# cslr_ul2_001 register map
Vendor: Texas Instruments
Peripheral module from a debugger description file.
Registers are 32-bit, read-write, reset 0x0 unless marked. A register's access mark holds for its fields unless they carry their own. Offsets are as the file gives them; lines under a group give offsets from that group; [hi:lo] are bit positions; {n}, {i} and the like mark numbered series; 'fields as' and 'values as' point back to an identical list; <NAME> marks a mode.

## UTOPIA2 — UNIVERSAL TEST AND OPERATIONS INTERFACE FOR ASYNCHRONOUS TRANSFER MODE
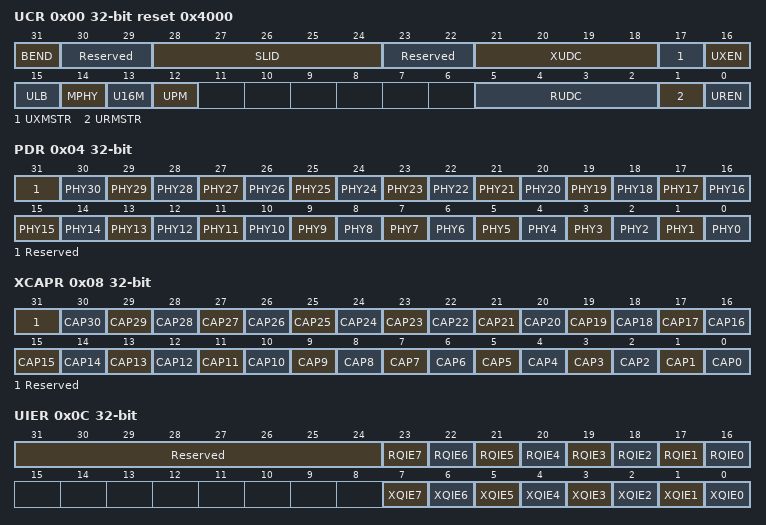
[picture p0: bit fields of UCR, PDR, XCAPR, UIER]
0x00 UCR access not given reset 0x4000 (reset mask 0x803FF03F) — UTOPIA Control Register
  [31] BEND rw — Endian Mode for data transferred via UTOPIA interface.
  [30:29] Reserved — (access N)
  [28:24] SLID SLEND rw — Slave ID: Applicable in Slave and MPHY mode.Slave END:Applicable in Master and MPHY mode.
  [23:22] Reserved — (access N)
  [21:18] XUDC rw — Transmit User Defined Cell
    0=? (Transmits standard ATM cell size of 53B); 11=? (Applicable for slave mode only. Transmits 11 extra header bytes)
  [17] UXMSTR rw — UTOPIA Transmit in master or slave mode selection
  [16] UXEN rw — UTOPIA Transmitter Enable
    0=? (UTOPIA port Transmitter Disabled and in reset state.); 1=? (UTOPIA port Transmitter Enabled.)
  [15] ULB rw — UTOPIA Loop Back Mode
    0=? (loop back mode disabled and normal UTOPIA operation); 1=? (loop back mode enabled.Master/Slave selection via U(R/X)MSTR)
  [14] MPHY rw — UTOPIA Receive/Transmit Multi-PHY Mode. MPHY mode is by default.
    0=? (Single PHY mode selected.); 1=? (Multi-PHY mode selected.)
  [13] U16M rw — 8-bit/16-bit Mode . 8-bit operation is default mode
    0=? (8-bit operation on both transmit and receive UTOPIA interface); 1=? (16-bit operation on both transmit and receive UTOPIA interface)
  [12] UPM rw — UTOPIA polling mode .Valid only when UMSTR=1
    0=? (Round-robin polling is used.); 1=? (Fixed address polling is used.)
  [5:2] RUDC rw — Receive User Defined Cell
    0=? (Receives standard ATM cell size of 53B); 11=? (Applicable for slave mode only. Receives 11 extra header bytes)
  [1] URMSTR rw — UTOPIA receive in master or slave mode selection
    0=? (Transmit and Receive interface are in slave mode :default state); 1=? (Transmit and Receive interface are in master mode)
  [0] UREN rw — UTOPIA Receiver Enable
    0=? (UTOPIA port receiver is disabled and in reset state); 1=? (UTOPIA port receiver is enabled)
0x04 PDR access not given (reset mask 0x7FFFFFFF) — PHY Disable Register
  [31] Reserved — (access N)
  [n] PHY{n} rw (n=0..30) — When Set PHY{n} is disabled
0x08 XCAPR access not given (reset mask 0x7FFFFFFF) — Transmit Cell Available for PHY Register(XCAPR)
  [31] Reserved — (access N)
  [n] CAP{n} ro (n=0..30) — Transmit Cell Available for PHY {n}
0x0C UIER access not given (reset mask 0xFF00FF) — UTOPIA Interrupt Enable Register
  [31:24] Reserved — (access N)
  [n+16] RQIE{n} rw (n=0..7) — Receive Queue Interrupt {n} enable
  [n] XQIE{n} rw (n=0..7) — Transmit Queue Interrupt {n} enable
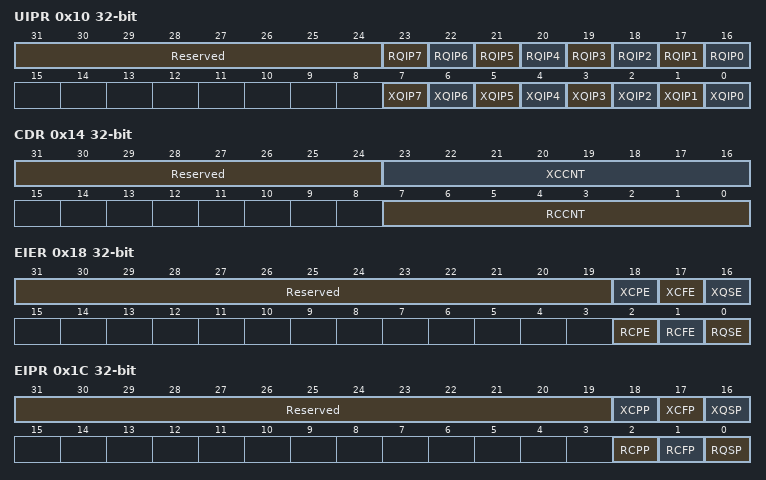
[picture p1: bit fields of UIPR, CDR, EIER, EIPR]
0x10 UIPR access not given (reset mask 0xFF00FF) — UTOPIA Interrupt Pending Register
  [31:24] Reserved — (access N)
  [n+16] RQIP{n} rw (n=0..7) — Receive Queue Interrupt Pending {n} is captured in UIPR
  [n] XQIP{n} rw (n=0..7) — Transmit Queue Interrupt Pending {n} is captured in UIPR
0x14 CDR access not given (reset mask 0xFF00FF) — Clock Detect Register
  [31:24] Reserved — (access N)
  [23:16] XCCNT rw — Transmit Interface Clock Count value.
    0=XCCNT (Transmit Clock Detection Disabled.)
  [7:0] RCCNT rw — Receive Interface Clock Count value.
    0=RCCNT (Receive Clock Detection disabled)
0x18 EIER access not given (reset mask 0x70007) — ERROR Interrupt Enable Register
  [31:19] Reserved — (access N)
  [18] XCPE rw — Transmit Clock Present Interrupt Enable
    0=XCPE (Transmit Clock Present Interrupt Disabled); 1=XCPE (Transmit Clock Present Interrupt Enabled)
  [17] XCFE rw — Transmit Clock Failed Interrupt Enable
    0=XCFE (Transmit Clock Failed Interrupt Disabled); 1=XCFE (Transmit Clock Failed Interrupt Enabled)
  [16] XQSE rw — Transmit Queue Stall Interrupt Enable
    0=XQSE (Transmit Queue Stall Interrupt Disabled); 1=XQSE (Transmit Queue Stall Interrupt Enabled)
  [2] RCPE rw — Receive Clock Present Interrupt Enable
    0=RCPE (Receive Clock Present Interrupt Disabled); 1=RCPE (Receive Clock Present Interrupt Enabled)
  [1] RCFE rw — Receive Clock Failed Interrupt Enable
    0=RCFE (Receive Clock Failed Interrupt Disabled); 1=RCFE (Receive Clock Failed Interrupt Enabled)
  [0] RQSE rw — Receive Queue Stall Interrupt Enable
    0=RQSE (Receive Queue Stall Interrupt Disabled); 1=RQSE (Receive Queue Stall Interrupt Enabled)
0x1C EIPR access not given (reset mask 0x70007) — Error Interrupt Pending Register
  [31:19] Reserved — (access N)
  [18] XCPP rw — Transmit Clock Present Interrupt Pending.XCPP is valid regardless if UXEN is set or not.
    0=XCPP (UXCLK not present.); 1=XCPP (UXCLK present. If the corresponding bit in the EIER is set,an interrupt UINT is sent to the CPU.)
  [17] XCFP rw — Transmit Clock Failed Interrupt Pending.Activated only when UXEN=1.
    0=XCFP (UXCLK present.); 1=XCFP (UXCLK failed. If the corresponding bit in the EIER is set,an interrupt UINT is sent to the CPU.)
  [16] XQSP rw — Transmit Queue Stall Interrupt Pending.Stalled untill the queue is drained and space is available.
    0=XQSP (No Transmit Queue Stall condition.); 1=XQSP (Transmit Queue Stalled.XQSP is cleared once the queue has space available and writes can continue.)
  [2] RCPP rw — Receive Clock Present Interrupt Pending.RCPP is valid regardless if UREN is set or not.
    0=RCPP (URCLK not Present); 1=RCPP (URCLK present. If the corresponding bit in the EIER is set,an interrupt UINT is sent to the CPU.)
  [1] RCFP rw — Receive Clock Failed Interrupt Pending.Activated only when UTOPIA Receive Interface(UREN=1)
    0=RCFP (URCLK present.); 1=RCFP (URCLK failed.If corresponding bit in EIER is set,an interrupt UINT is sent to the CPU.)
  [0] RQSP rw — Receive Queue Stall Interrupt Pending
    0=RQSP (No Receive Queue Stall Condition); 1=RQSP (Receive Queue Stalled.RQSP is cleared as soon as Valid data is available and the read is performed.)
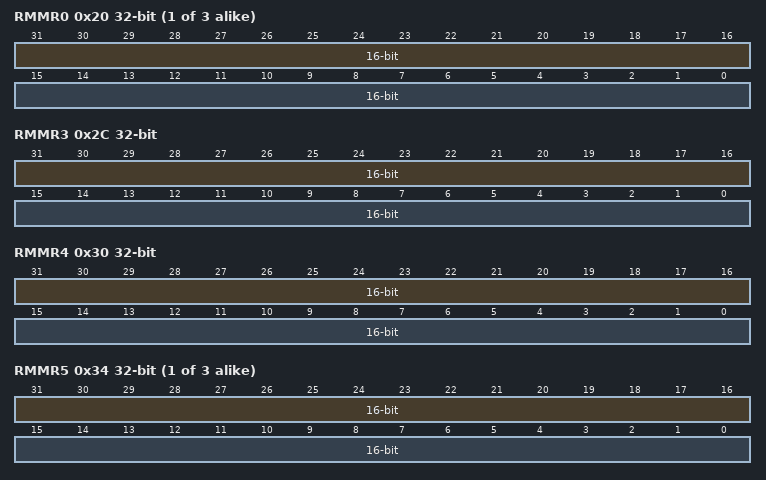
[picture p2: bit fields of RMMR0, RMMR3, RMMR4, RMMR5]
{0x20+4i} RMMR{i} (i=0..2) — Receive Mask-Match Register {i}
  [31:16] 16-bit MATCH value, [15:0] 16-bit MASK value
0x2C RMMR3 — Receive Mask-Match register3
  [31:16] 16-bit MATCH value, [15:0] 16-bit MASK value
0x30 RMMR4 — Receive Mask-Match Register4
  [31:16] 16-bit MATCH value, [15:0] 16-bit MASK value
{0x20+4i} RMMR{i} (i=5..7) — Receive Mask-Match register{i}
  [31:16] 16-bit MATCH value, [15:0] 16-bit MASK value
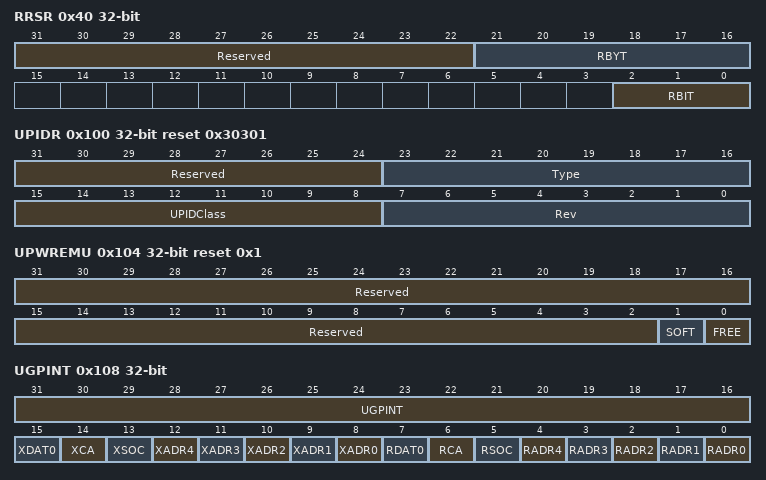
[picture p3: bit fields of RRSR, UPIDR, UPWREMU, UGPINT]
0x40 RRSR access not given (reset mask 0x3F0007) — Receive Routing Select Register
  [31:22] Reserved — (access N)
  [21:16] RBYT rw — Indicates Least Significant Byte of the 16-bit field of interest.
  [2:0] RBIT rw — Indicates the least significant bit within the 16-bit field of interest that is used for routing decisions.
0x100 UPIDR access not given reset 0x30301 (reset mask 0xFFFFFF) — Register to identify the peripheral for revision number,class,and type.
  [31:24] Reserved — (access N)
  [23:16] Type ro — The Type of peripheral specifies the actual peripheral within a peripheral Class. For UTOPIA, the Class in the UIPDR[Class] defines UTOPIA Level 2 interface.
  [15:8] UPIDClass ro — The Class indicates if the peripheral is a Host interface, DMA controller, or a Network Interface, etc. UTOPIA belongs to the Class - Network Interface that always carries a value '3'.
  [7:0] Rev ro — Reserved
0x104 UPWREMU access not given reset 0x1 (reset mask 0x3) — UTOPIA Power Management and Emulation Register
  [31:2] Reserved — (access N)
  [1] SOFT rw — This Bit has no effect when FREE=1.
    0=SOFT (Undefined Operation); 1=SOFT (In Slave mode all on-going operations should be complete.In master Mode Mode: Current data transfer on the pins should complete and pending read/write requests to/from CPU/DMA should complete before emulation halt.)
  [0] FREE rw — This Bit in conjunction with SOFT bit determines Emulation operation
    0=FREE (SOFT bit controls Emulation During Emulation Halt); 1=FREE (Emulation has no effect on UTOPIA port Operation.Peripheral operates Normally.)
0x108 UGPINT — GPIO Interrupts are Enabled
  [31:16] UGPINT — GPIO Interrupt Negation/Polarity
    0=UGPINT[x] (GPIO interrupt not inverted. Polarity remains same as that at the pin(s).); 1=UGPINT[x] (Relevant GPIO interrupt is inverted. It could be any of the pins.)
  [15] XDAT0 — Transmit data 0
    0=XDAT0 (GPIO interrupt disabled.); 1=XDAT1 (1, Low-to-high transition on the UXData[0] pin causes interrupt RQIP0 to CPU via UIPR and UIER. It can also generate DMA event XEVT0.)
  [14] XCA — Transmit Cell Available
    0=XCA (GPIO interrupt disabled.); 1=XCA (Low-to-high transition on the UXClav pin causes interrupt XQIP1 to CPU via UIPR and UIER. It can also generate DMA event XEVT1)
  [13] XSOC — Transmit Start of Cell
    0=XSOC (GPIO interrupt disabled.); 1=XSOC (Low-to-high transition on the UXSOC pin causes interrupt XQIP2 to CPU via UIPR and UIER. It can also generate DMA event XEVT2.)
  [n+8] XADR{n} (n=0..4) — Transmit address{n}
  [7] RDAT0 — Receive data0
    0=RDAT0 (GPIO interrupt disabled.); 1=RDAT1 (1, Low-to-high transition on the URData[0] pin causes interrupt RQIP0 to CPU via UIPR and UIER. It can also generate DMA event REVT0.)
  [6] RCA — Receive Cell Available
    0=RCA (GPIO interrupt Disabled.); 1=RCA (Low-to-high transition on the URClav pin causes interrupt RQIP1 to CPU via UIPR and UIER. It can also generate DMA event REVT1.)
  [5] RSOC — Receive Start of Cell
    0=RSOC (GPIO interrupt Disabled.); 1=RSOC (Low-to-high transition on the URSOC pin causes interrupt RQIP2 to CPU via UIPR and UIER. It can also generate DMA event REVT2.)
  [4] RADR4
  [3] RADR3 — REVT[7:3].
  [2] RADR2 — corresponding interrupts RQIP[7:3] to CPU via UIPR and UIER. It can also generate DMA event
  [1] RADR1 — RADR [4:0] = 1, Low-to-high transition on the Receive Address pins URAddr[4:0] cause
  [0] RADR0 — RADR [4:0] = 0, GPIO interrupt disabled.
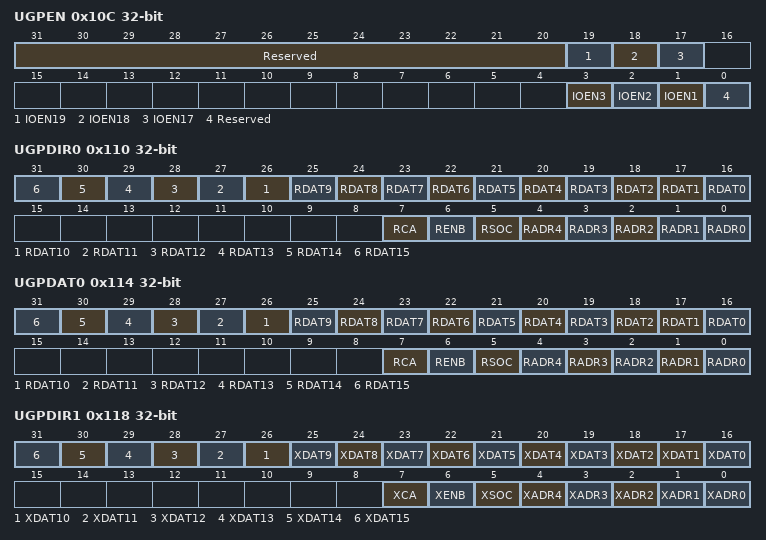
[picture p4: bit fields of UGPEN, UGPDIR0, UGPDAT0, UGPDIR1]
0x10C UGPEN access not given (reset mask 0xE000E) — UTOPIA GPIO Enable Register
  [31:20] Reserved — (access N)
  [19] IOEN19 rw — UXSoc and UXAddr[4:0] are used as GPIO.
  [18] IOEN18 rw — UXEnb and UXClav are used as GPIO
  [17] IOEN17 rw — UXDATA[15:0] are used for GPIO (8-bits for utopia-8 and 16-bits for utopia-16)
  [3] IOEN3 rw — Utopia pins URSOC and URAddr[4:0] are controlled as GPIO
  [2] IOEN2 rw — UREnb and URClav pins are Controlled as GPIO
  [1] IOEN1 rw — URData[15:0] are used for GPIO (8-bits for utopia-8 and 16-bits for utopia-16)
  [0] Reserved — (access N)
0x110 UGPDIR0 — Controls the Direction of IO pins
  [n+16] RDAT{n} (n=2..15) — Receive data{n} pin is monitored to be GPIO
  [17] RDAT1 — Receive data1as GPIO
  [16] RDAT0 — Receive data0 as GPIO
  [7] RCA — Monitoring Receive Cell as GPIO.
  [6] RENB — Monitoring Receive enable as GPIO
  [5] RSOC — Monitoring Receive Start of Cell as GPIO
  [n] RADR{n} (n=1..4) — Monitoring Receive address{n} as GPIO
  [0] RADR0 — Monitoring of Receive address0 pin as GPIO
0x114 UGPDAT0 — Indicates logic levels at the corresponding pins
  [n+16] RDAT{n} (n=2..15) — Data Available/to be written on Receive data{n} as configured in control register
  [17] RDAT1 — Data Available/to be written on Receivedata1 as configured in control register
  [16] RDAT0 — Data Available/to be written on Receive data0 as configured in control register
  [7] RCA — Data Available/to be written on Receive Cell Available pin as configured in control register
  [6] RENB — Data Available/to be written on Receive enable pin as configured in control register
  [5] RSOC — Data Available/to be written on Receive Start of Cell pin as configured in control register
  [4] RADR4 — Data Available/to be written on Receive address4 as configured in control register
  [3] RADR3 — Data Available/to be written on Receive address3 as configured in control register
  [2] RADR2 — Data Available/tobe written on Receive address2 as configured in control register
  [1] RADR1 — Data Available/to be written on Receive address1 as configured in control register
  [0] RADR0 — Data Available/to be written on Receive address0 as configured in control register
0x118 UGPDIR1 — Controls the Direction of IO pins
  [n+16] XDAT{n} (n=2..15) — Transmit data{n} pin is monitored to be GPIO
  [17] XDAT1 — Transmit data1as GPIO
  [16] XDAT0 — Transmit data0 as GPIO
  [7] XCA — Monitoring Transmit Cell as GPIO.
  [6] XENB — Monitoring Transmit enable as GPIO
  [5] XSOC — Monitoring Transmit Start of Cell as GPIO
  [n] XADR{n} (n=1..4) — Monitoring Transmit address{n} as GPIO
  [0] XADR0 — Monitoring of Transmit address0 pin as GPIO
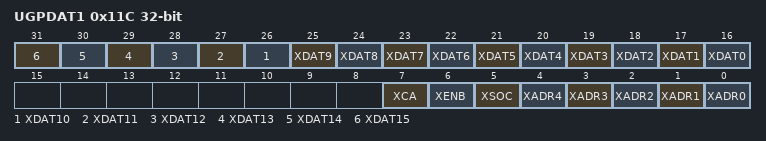
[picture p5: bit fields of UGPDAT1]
0x11C UGPDAT1 — Indicates the levels of corresponding pins
  [n+16] XDAT{n} (n=3..15) — Data Available/to be written on Transmit data{n} as configured in control register
  [18] XDAT2 — Data Available/to be written onTransmit data2 as configured in control register
  [17] XDAT1 — Data Available/to be written on Transmit data1 as configured in control register
  [16] XDAT0 — Data Available/to be written on Transmit data0 as configured in control register
  [7] XCA — Data Available/to be written onTransmit Cell Available pin as configured in control register
  [6] XENB — Data Available/to be written on Transmit enable pin as configured in control register
  [5] XSOC — Data Available/to be written on Transmit Start of Cell pin as configured in control register
  [4] XADR4 — Data Available/to be written onTransmit address4 as configured in control register
  [3] XADR3 — Data Available/to be written on Transmit address3 as configured in control register
  [2] XADR2 — Data Available/tobe written on Transmit address2 as configured in control register
  [1] XADR1 — Data Available/to be written on Transmit address1 as configured in control register
  [0] XADR0 — Data Available/to be written on Transmit address0 as configured in control register
0x120 UGPDIR2 ro — Controls the Direction of IO pins
0x124 UGPDAT2 ro — Indicates the levels of corresponding pins
0x128 UGPDIR3 ro — Controls the Direction of IO pins
0x12C UGPDAT3 ro — Indicates the levels of corresponding pins
